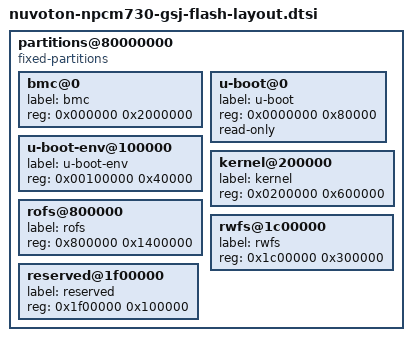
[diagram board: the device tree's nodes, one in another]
// SPDX-License-Identifier: GPL-2.0+

partitions@80000000 {
        compatible = "fixed-partitions";
        #address-cells = <1>;
        #size-cells = <1>;
        bmc@0{
            label = "bmc";
            reg = <0x000000 0x2000000>;
        };
        u-boot@0 {
            label = "u-boot";
            reg = <0x0000000 0x80000>;
            read-only;
        };
        u-boot-env@100000{
            label = "u-boot-env";
            reg = <0x00100000 0x40000>;
        };
        kernel@200000 {
            label = "kernel";
            reg = <0x0200000 0x600000>;
        };
        rofs@800000 {
            label = "rofs";
            reg = <0x800000 0x1400000>;
        };
        rwfs@1c00000 {
            label = "rwfs";
            reg = <0x1c00000 0x300000>;
        };
        reserved@1f00000 {
            label = "reserved";
            reg = <0x1f00000 0x100000>;
        };
};
